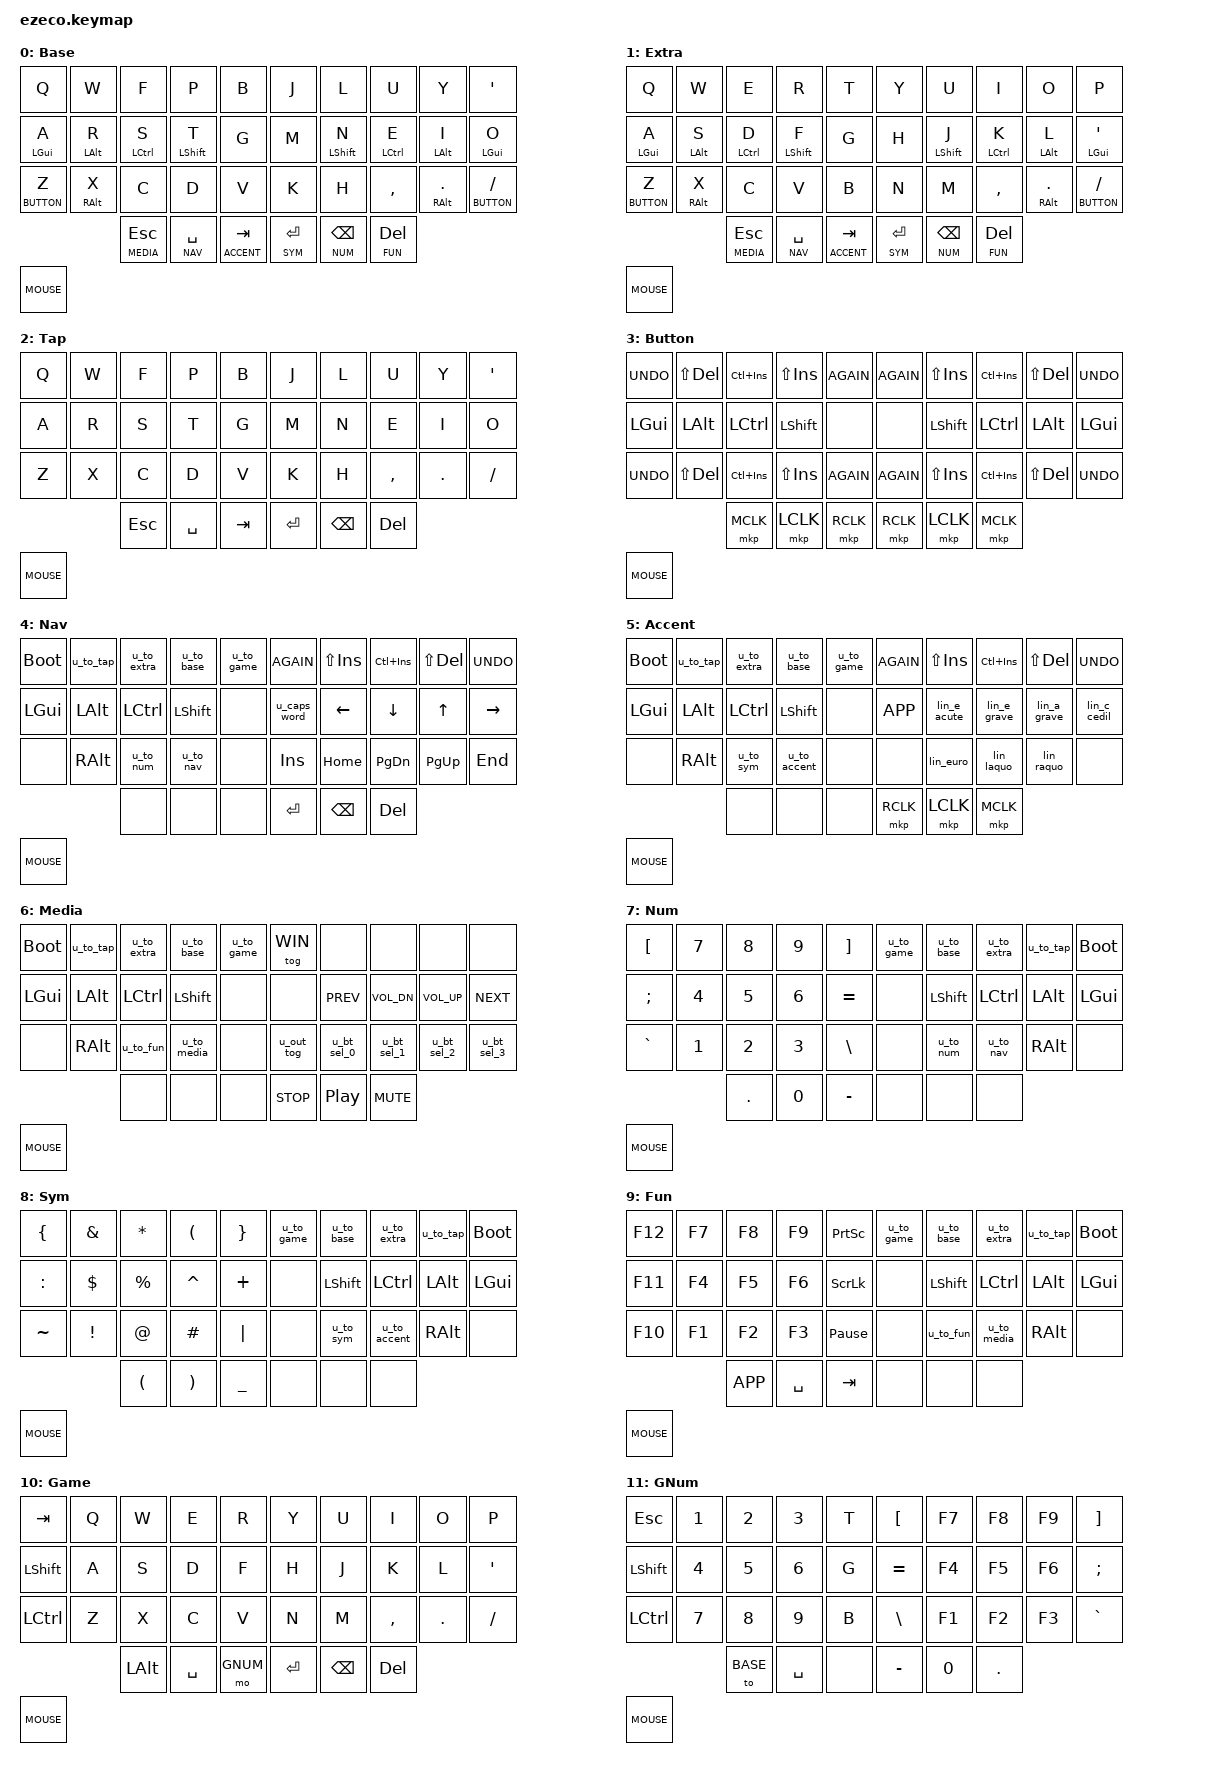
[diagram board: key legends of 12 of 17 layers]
/*
 * ezeco keymap: Miryoku Colemak-DH (manna-harbour/miryoku, default options) as a plain
 * ZMK keymap, plus:
 *   - Game / GNum layers (from mnivoliez/miryoku_zmk custom_config.h), entered with a
 *     double-tap key on the layer-switch row (replaces the old outer-column key);
 *   - Accent layer (Miryoku's Mouse layer, renamed): French characters with a Linux/Windows
 *     mode, mouse buttons kept on the right thumbs;
 *   - Ball layer: turns on by itself when the trackball moves (clicks, scroll, precision).
 * Lives on the dongle.
 *
 * Key positions (44):
 *   0-9    top row        left pinky..inner (0-4)   right inner..pinky (5-9)
 *   10-19  home row
 *   20-29  bottom row
 *   30-35  thumbs         left outer..inner (30-32) right inner..outer (33-35)
 *   36-43  mouse          L, R, M, back, forward, DPI, tilt left, tilt right
 *
 * Linux: enable the Compose key on Menu (xkb option compose:menu).
 * Windows: Accent characters use Alt codes, NumLock must be on.
 */

#include <behaviors.dtsi>
#include <dt-bindings/zmk/bt.h>
#include <dt-bindings/zmk/keys.h>
#include <dt-bindings/zmk/outputs.h>
#include <dt-bindings/zmk/pointing.h>
#include <input/processors.dtsi>

#define BASE       0
#define EXTRA      1
#define TAP        2
#define BUTTON     3
#define NAV        4
#define ACCENT     5
#define MEDIA      6
#define NUM        7
#define SYM        8
#define FUN        9
#define GAME      10
#define GNUM      11
#define WIN       12
#define ACCENT_W  13
#define BALL      14
#define SCROLL    15
#define PREC      16

#define XXX &none

// Miryoku default clipboard keys.
#define U_RDO &kp K_AGAIN
#define U_PST &kp LS(INS)
#define U_CPY &kp LC(INS)
#define U_CUT &kp LS(DEL)
#define U_UND &kp K_UNDO

// Mouse device buttons: identical on every layer.
#define MOUSE &mkp LCLK &mkp RCLK &mkp MCLK &mkp MB4 &mkp MB5 XXX &msc SCRL_LEFT &msc SCRL_RIGHT

// Double-tap guard (Miryoku): a single tap does nothing, a double tap runs the binding.
#define DT_GUARD(name, action) \
    name: name { \
        compatible = "zmk,behavior-tap-dance"; \
        #binding-cells = <0>; \
        tapping-term-ms = <200>; \
        bindings = <&none>, <action>; \
    };

// Linux: Compose (Menu key) sequence.
#define LIN(name, ...) \
    name: name { \
        compatible = "zmk,behavior-macro"; \
        #binding-cells = <0>; \
        bindings = <&macro_tap &kp K_APP __VA_ARGS__>; \
    };

// Windows: Alt code typed on the numpad (NumLock on).
#define WIN_ALT(name, a, b, c, d) \
    name: name { \
        compatible = "zmk,behavior-macro"; \
        #binding-cells = <0>; \
        bindings \
            = <&macro_press &kp LALT> \
            , <&macro_tap &kp KP_N##a &kp KP_N##b &kp KP_N##c &kp KP_N##d> \
            , <&macro_release &kp LALT> \
            ; \
    };

// Lowercase, or uppercase when Shift is held.
#define CASE(name, lower, upper) \
    name: name { \
        compatible = "zmk,behavior-mod-morph"; \
        #binding-cells = <0>; \
        bindings = <lower>, <upper>; \
        mods = <(MOD_LSFT|MOD_RSFT)>; \
    };

// Miryoku shift functions.
#define U_BT_SEL(n) \
    u_bt_sel_##n: u_bt_sel_##n { \
        compatible = "zmk,behavior-mod-morph"; \
        #binding-cells = <0>; \
        bindings = <&bt BT_SEL n>, <&u_bt_clr_##n>; \
        mods = <(MOD_LSFT|MOD_RSFT)>; \
    }; \
    u_bt_clr_##n: u_bt_clr_##n { \
        compatible = "zmk,behavior-macro"; \
        #binding-cells = <0>; \
        bindings = <&macro_tap &bt BT_SEL n &bt BT_CLR>; \
    };

/ {
    behaviors {
        u_mt: u_mt {
            compatible = "zmk,behavior-hold-tap";
            #binding-cells = <2>;
            tapping-term-ms = <200>;
            flavor = "tap-preferred";
            bindings = <&kp>, <&kp>;
        };

        u_lt: u_lt {
            compatible = "zmk,behavior-hold-tap";
            #binding-cells = <2>;
            tapping-term-ms = <200>;
            flavor = "tap-preferred";
            bindings = <&mo>, <&kp>;
        };

        DT_GUARD(u_to_base, &to BASE)
        DT_GUARD(u_to_extra, &to EXTRA)
        DT_GUARD(u_to_tap, &to TAP)
        DT_GUARD(u_to_nav, &to NAV)
        DT_GUARD(u_to_accent, &to ACCENT)
        DT_GUARD(u_to_media, &to MEDIA)
        DT_GUARD(u_to_num, &to NUM)
        DT_GUARD(u_to_sym, &to SYM)
        DT_GUARD(u_to_fun, &to FUN)
        DT_GUARD(u_to_game, &to GAME)

        u_caps_word: u_caps_word {
            compatible = "zmk,behavior-mod-morph";
            #binding-cells = <0>;
            bindings = <&caps_word>, <&kp CAPS>;
            mods = <(MOD_LSFT|MOD_RSFT)>;
        };

        u_out_tog: u_out_tog {
            compatible = "zmk,behavior-mod-morph";
            #binding-cells = <0>;
            bindings = <&out OUT_TOG>, <&out OUT_USB>;
            mods = <(MOD_LSFT|MOD_RSFT)>;
        };

        U_BT_SEL(0)
        U_BT_SEL(1)
        U_BT_SEL(2)
        U_BT_SEL(3)

        // Mouse wheel. TODO: tune feel in step M2 (may move to an input processor instead).
        scroll_wheel: scroll_wheel {
            compatible = "zmk,behavior-sensor-rotate";
            #sensor-binding-cells = <0>;
            bindings = <&msc SCRL_DOWN>, <&msc SCRL_UP>;
        };
    };

    macros {
        // French characters, Linux (Compose).
        LIN(lin_e_acute_l, &kp SQT &kp E)
        LIN(lin_e_acute_u, &kp SQT &kp LS(E))
        LIN(lin_e_grave_l, &kp GRAVE &kp E)
        LIN(lin_e_grave_u, &kp GRAVE &kp LS(E))
        LIN(lin_a_grave_l, &kp GRAVE &kp A)
        LIN(lin_a_grave_u, &kp GRAVE &kp LS(A))
        LIN(lin_c_cedil_l, &kp COMMA &kp C)
        LIN(lin_c_cedil_u, &kp COMMA &kp LS(C))
        LIN(lin_laquo, &kp LT &kp LT)
        LIN(lin_raquo, &kp GT &kp GT)
        LIN(lin_euro, &kp EQUAL &kp E)

        // French characters, Windows (Alt codes).
        WIN_ALT(win_e_acute_l, 0, 2, 3, 3)
        WIN_ALT(win_e_acute_u, 0, 2, 0, 1)
        WIN_ALT(win_e_grave_l, 0, 2, 3, 2)
        WIN_ALT(win_e_grave_u, 0, 2, 0, 0)
        WIN_ALT(win_a_grave_l, 0, 2, 2, 4)
        WIN_ALT(win_a_grave_u, 0, 1, 9, 2)
        WIN_ALT(win_c_cedil_l, 0, 2, 3, 1)
        WIN_ALT(win_c_cedil_u, 0, 1, 9, 9)
        WIN_ALT(win_laquo, 0, 1, 7, 1)
        WIN_ALT(win_raquo, 0, 1, 8, 7)
        WIN_ALT(win_euro, 0, 1, 2, 8)
    };

    behaviors {
        CASE(lin_e_acute, &lin_e_acute_l, &lin_e_acute_u)
        CASE(lin_e_grave, &lin_e_grave_l, &lin_e_grave_u)
        CASE(lin_a_grave, &lin_a_grave_l, &lin_a_grave_u)
        CASE(lin_c_cedil, &lin_c_cedil_l, &lin_c_cedil_u)
        CASE(win_e_acute, &win_e_acute_l, &win_e_acute_u)
        CASE(win_e_grave, &win_e_grave_l, &win_e_grave_u)
        CASE(win_a_grave, &win_a_grave_l, &win_a_grave_u)
        CASE(win_c_cedil, &win_c_cedil_l, &win_c_cedil_u)
    };

    // Accent + Win mode = Windows variant of the Accent layer.
    conditional_layers {
        compatible = "zmk,conditional-layers";
        accent_win {
            if-layers = <ACCENT WIN>;
            then-layer = <ACCENT_W>;
        };
    };

    keymap {
        compatible = "zmk,keymap";

        base_layer {
            display-name = "Base";
            bindings = <
&kp Q              &kp W              &kp F              &kp P              &kp B              &kp J              &kp L              &kp U              &kp Y              &kp SQT
&u_mt LGUI A       &u_mt LALT R       &u_mt LCTRL S      &u_mt LSHFT T      &kp G              &kp M              &u_mt LSHFT N      &u_mt LCTRL E      &u_mt LALT I       &u_mt LGUI O
&u_lt BUTTON Z     &u_mt RALT X       &kp C              &kp D              &kp V              &kp K              &kp H              &kp COMMA          &u_mt RALT DOT     &u_lt BUTTON SLASH
                                      &u_lt MEDIA ESC    &u_lt NAV SPACE    &u_lt ACCENT TAB   &u_lt SYM RET      &u_lt NUM BSPC     &u_lt FUN DEL
MOUSE
            >;
            sensor-bindings = <&scroll_wheel>;
        };

        extra_layer {
            display-name = "Extra";
            bindings = <
&kp Q              &kp W              &kp E              &kp R              &kp T              &kp Y              &kp U              &kp I              &kp O              &kp P
&u_mt LGUI A       &u_mt LALT S       &u_mt LCTRL D      &u_mt LSHFT F      &kp G              &kp H              &u_mt LSHFT J      &u_mt LCTRL K      &u_mt LALT L       &u_mt LGUI SQT
&u_lt BUTTON Z     &u_mt RALT X       &kp C              &kp V              &kp B              &kp N              &kp M              &kp COMMA          &u_mt RALT DOT     &u_lt BUTTON SLASH
                                      &u_lt MEDIA ESC    &u_lt NAV SPACE    &u_lt ACCENT TAB   &u_lt SYM RET      &u_lt NUM BSPC     &u_lt FUN DEL
MOUSE
            >;
            sensor-bindings = <&scroll_wheel>;
        };

        tap_layer {
            display-name = "Tap";
            bindings = <
&kp Q              &kp W              &kp F              &kp P              &kp B              &kp J              &kp L              &kp U              &kp Y              &kp SQT
&kp A              &kp R              &kp S              &kp T              &kp G              &kp M              &kp N              &kp E              &kp I              &kp O
&kp Z              &kp X              &kp C              &kp D              &kp V              &kp K              &kp H              &kp COMMA          &kp DOT            &kp SLASH
                                      &kp ESC            &kp SPACE          &kp TAB            &kp RET            &kp BSPC           &kp DEL
MOUSE
            >;
            sensor-bindings = <&scroll_wheel>;
        };

        button_layer {
            display-name = "Button";
            bindings = <
U_UND              U_CUT              U_CPY              U_PST              U_RDO              U_RDO              U_PST              U_CPY              U_CUT              U_UND
&kp LGUI           &kp LALT           &kp LCTRL          &kp LSHFT          XXX                XXX                &kp LSHFT          &kp LCTRL          &kp LALT           &kp LGUI
U_UND              U_CUT              U_CPY              U_PST              U_RDO              U_RDO              U_PST              U_CPY              U_CUT              U_UND
                                      &mkp MCLK          &mkp LCLK          &mkp RCLK          &mkp RCLK          &mkp LCLK          &mkp MCLK
MOUSE
            >;
            sensor-bindings = <&scroll_wheel>;
        };

        nav_layer {
            display-name = "Nav";
            bindings = <
&bootloader        &u_to_tap          &u_to_extra        &u_to_base         &u_to_game         U_RDO              U_PST              U_CPY              U_CUT              U_UND
&kp LGUI           &kp LALT           &kp LCTRL          &kp LSHFT          XXX                &u_caps_word       &kp LEFT           &kp DOWN           &kp UP             &kp RIGHT
XXX                &kp RALT           &u_to_num          &u_to_nav          XXX                &kp INS            &kp HOME           &kp PG_DN          &kp PG_UP          &kp END
                                      XXX                XXX                XXX                &kp RET            &kp BSPC           &kp DEL
MOUSE
            >;
            sensor-bindings = <&scroll_wheel>;
        };

        // Miryoku's Mouse layer: pointer keys replaced by French characters (Linux mode).
        accent_layer {
            display-name = "Accent";
            bindings = <
&bootloader        &u_to_tap          &u_to_extra        &u_to_base         &u_to_game         U_RDO              U_PST              U_CPY              U_CUT              U_UND
&kp LGUI           &kp LALT           &kp LCTRL          &kp LSHFT          XXX                &kp K_APP          &lin_e_acute       &lin_e_grave       &lin_a_grave       &lin_c_cedil
XXX                &kp RALT           &u_to_sym          &u_to_accent       XXX                XXX                &lin_euro          &lin_laquo         &lin_raquo         XXX
                                      XXX                XXX                XXX                &mkp RCLK          &mkp LCLK          &mkp MCLK
MOUSE
            >;
            sensor-bindings = <&scroll_wheel>;
        };

        media_layer {
            display-name = "Media";
            bindings = <
&bootloader        &u_to_tap          &u_to_extra        &u_to_base         &u_to_game         &tog WIN           XXX                XXX                XXX                XXX
&kp LGUI           &kp LALT           &kp LCTRL          &kp LSHFT          XXX                XXX                &kp C_PREV         &kp C_VOL_DN       &kp C_VOL_UP       &kp C_NEXT
XXX                &kp RALT           &u_to_fun          &u_to_media        XXX                &u_out_tog         &u_bt_sel_0        &u_bt_sel_1        &u_bt_sel_2        &u_bt_sel_3
                                      XXX                XXX                XXX                &kp C_STOP         &kp C_PP           &kp C_MUTE
MOUSE
            >;
            sensor-bindings = <&scroll_wheel>;
        };

        num_layer {
            display-name = "Num";
            bindings = <
&kp LBKT           &kp N7             &kp N8             &kp N9             &kp RBKT           &u_to_game         &u_to_base         &u_to_extra        &u_to_tap          &bootloader
&kp SEMI           &kp N4             &kp N5             &kp N6             &kp EQUAL          XXX                &kp LSHFT          &kp LCTRL          &kp LALT           &kp LGUI
&kp GRAVE          &kp N1             &kp N2             &kp N3             &kp BSLH           XXX                &u_to_num          &u_to_nav          &kp RALT           XXX
                                      &kp DOT            &kp N0             &kp MINUS          XXX                XXX                XXX
MOUSE
            >;
            sensor-bindings = <&scroll_wheel>;
        };

        sym_layer {
            display-name = "Sym";
            bindings = <
&kp LBRC           &kp AMPS           &kp ASTRK          &kp LPAR           &kp RBRC           &u_to_game         &u_to_base         &u_to_extra        &u_to_tap          &bootloader
&kp COLON          &kp DLLR           &kp PRCNT          &kp CARET          &kp PLUS           XXX                &kp LSHFT          &kp LCTRL          &kp LALT           &kp LGUI
&kp TILDE          &kp EXCL           &kp AT             &kp HASH           &kp PIPE           XXX                &u_to_sym          &u_to_accent       &kp RALT           XXX
                                      &kp LPAR           &kp RPAR           &kp UNDER          XXX                XXX                XXX
MOUSE
            >;
            sensor-bindings = <&scroll_wheel>;
        };

        fun_layer {
            display-name = "Fun";
            bindings = <
&kp F12            &kp F7             &kp F8             &kp F9             &kp PSCRN          &u_to_game         &u_to_base         &u_to_extra        &u_to_tap          &bootloader
&kp F11            &kp F4             &kp F5             &kp F6             &kp SLCK           XXX                &kp LSHFT          &kp LCTRL          &kp LALT           &kp LGUI
&kp F10            &kp F1             &kp F2             &kp F3             &kp PAUSE_BREAK    XXX                &u_to_fun          &u_to_media        &kp RALT           XXX
                                      &kp K_APP          &kp SPACE          &kp TAB            XXX                XXX                XXX
MOUSE
            >;
            sensor-bindings = <&scroll_wheel>;
        };

        // FPS-friendly layer from mnivoliez/miryoku_zmk. Leave with GNum + left outer thumb.
        game_layer {
            display-name = "Game";
            bindings = <
&kp TAB            &kp Q              &kp W              &kp E              &kp R              &kp Y              &kp U              &kp I              &kp O              &kp P
&kp LSHFT          &kp A              &kp S              &kp D              &kp F              &kp H              &kp J              &kp K              &kp L              &kp SQT
&kp LCTRL          &kp Z              &kp X              &kp C              &kp V              &kp N              &kp M              &kp COMMA          &kp DOT            &kp SLASH
                                      &kp LALT           &kp SPACE          &mo GNUM           &kp RET            &kp BSPC           &kp DEL
MOUSE
            >;
            sensor-bindings = <&scroll_wheel>;
        };

        gnum_layer {
            display-name = "GNum";
            bindings = <
&kp ESC            &kp N1             &kp N2             &kp N3             &kp T              &kp LBKT           &kp F7             &kp F8             &kp F9             &kp RBKT
&kp LSHFT          &kp N4             &kp N5             &kp N6             &kp G              &kp EQUAL          &kp F4             &kp F5             &kp F6             &kp SEMI
&kp LCTRL          &kp N7             &kp N8             &kp N9             &kp B              &kp BSLH           &kp F1             &kp F2             &kp F3             &kp GRAVE
                                      &to BASE           &kp SPACE          XXX                &kp MINUS          &kp N0             &kp DOT
MOUSE
            >;
            sensor-bindings = <&scroll_wheel>;
        };

        // Windows mode flag (toggled on Media). Empty on purpose.
        win_layer {
            display-name = "Win";
            bindings = <
&trans &trans &trans &trans &trans &trans &trans &trans &trans &trans
&trans &trans &trans &trans &trans &trans &trans &trans &trans &trans
&trans &trans &trans &trans &trans &trans &trans &trans &trans &trans
                     &trans &trans &trans &trans &trans &trans
&trans &trans &trans &trans &trans &trans &trans &trans
            >;
        };

        // Accent in Windows mode (conditional layer): Alt codes, no Compose.
        accent_win_layer {
            display-name = "Accent Win";
            bindings = <
&trans             &trans             &trans             &trans             &trans             &trans             &trans             &trans             &trans             &trans
&trans             &trans             &trans             &trans             &trans             XXX                &win_e_acute       &win_e_grave       &win_a_grave       &win_c_cedil
&trans             &trans             &trans             &trans             &trans             &trans             &win_euro          &win_laquo         &win_raquo         &trans
                                      &trans             &trans             &trans             &trans             &trans             &trans
&trans &trans &trans &trans &trans &trans &trans &trans
            >;
        };

        // Turns on when the trackball moves (see trackball_listener below).
        ball_layer {
            display-name = "Ball";
            bindings = <
&trans             &trans             &trans             &trans             &trans             &trans             &tog PREC          &tog SCROLL        &trans             &trans
&trans             &trans             &trans             &trans             &trans             &trans             &mkp LCLK          &mkp MCLK          &mkp RCLK          &trans
&trans             &trans             &trans             &trans             &trans             &trans             &trans             &trans             &trans             &trans
                                      &trans             &trans             &trans             &trans             &trans             &trans
&trans &trans &trans &trans &trans &trans &trans &trans
            >;
        };

        // Mode flags for the trackball. Empty on purpose; the Prospector shows their names.
        scroll_layer {
            display-name = "Scroll";
            bindings = <
&trans &trans &trans &trans &trans &trans &trans &trans &trans &trans
&trans &trans &trans &trans &trans &trans &trans &trans &trans &trans
&trans &trans &trans &trans &trans &trans &trans &trans &trans &trans
                     &trans &trans &trans &trans &trans &trans
&trans &trans &trans &trans &trans &trans &trans &trans
            >;
        };

        prec_layer {
            display-name = "Precise";
            bindings = <
&trans &trans &trans &trans &trans &trans &trans &trans &trans &trans
&trans &trans &trans &trans &trans &trans &trans &trans &trans &trans
&trans &trans &trans &trans &trans &trans &trans &trans &trans &trans
                     &trans &trans &trans &trans &trans &trans
&trans &trans &trans &trans &trans &trans &trans &trans
            >;
        };
    };
};

/*
 * Ball layer: on when the ball moves, off 800 ms after it stops, or when a key
 * outside the Ball keys and the left home row (for Ctrl/Shift+click) is pressed. Ignores
 * movement within 200 ms of typing, so brushing the ball while typing does nothing.
 */
&zip_temp_layer {
    require-prior-idle-ms = <200>;
    excluded-positions = <6 7 10 11 12 13 16 17 18>;
};

// TODO: tune speeds once the PAW3395 is on the right half (step H3).
&trackball_listener {
    input-processors = <&zip_temp_layer BALL 800>;

    scroll_mode {
        layers = <SCROLL>;
        input-processors = <&zip_xy_to_scroll_mapper &zip_scroll_scaler 1 16>;
    };

    precise_mode {
        layers = <PREC>;
        input-processors = <&zip_xy_scaler 1 3 &zip_temp_layer BALL 800>;
    };
};
